# RTS591x register map
Vendor: Realtek Semiconductor Corp.; Series: RTS591x Series; File version: 1.0
CPU: ARMV8MML r0p0, little endian, MPU, FPU, VTOR, 3 interrupt priority bits, 4 SAU regions
Registers are 32-bit, read-write, reset 0x0 unless marked. A register's access mark holds for its fields unless they carry their own. Offsets are from the block's base; [hi:lo] are bit positions.

## RTC — RTC Controller
Base 0x4000C100
0x00 SEC 8-bit — SECOND REGISTER
0x01 SECALARM 8-bit — SECOND ALARM REGISTER
0x02 MIN 8-bit — MINUTES REGISTER
0x03 MINALARM 8-bit — MINUTES ALARM REGISTER
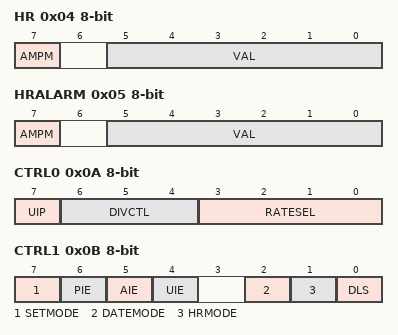
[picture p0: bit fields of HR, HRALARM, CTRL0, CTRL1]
0x04 HR 8-bit — HOUR REGISTER
  [7] AMPM — AM or PM Mode
  [5:0] VAL — Value of Hour
0x05 HRALARM 8-bit — HOUR ALARM REGISTER
  [7] AMPM — AM or PM Mode of Hour Alarm
  [5:0] VAL — Value of Hour Alarm
0x06 DAYWEEK 8-bit — DAY OF WEEK REGISTER
0x07 DAYMONTH 8-bit — DAY OF MONTH REGISTER
0x08 MONTH 8-bit
0x09 YEAR 8-bit
0x0A CTRL0 8-bit — CONTROL REGISTER #0
  [7] UIP — Update In Progress
    0=NOT_IN_PROGRESS (Time registers will not update in 244us); 1=IN_PROGRESS (Time registers will update in 244us)
  [6:4] DIVCTL — Divider Chain Control
    1=NORMAL (Normal operation); 6=DVDRST (Divider Chain Reset); other=NOT_USED (Do not use.)
  [3:0] RATESEL — Periodic Interrupt Rate Select
    0=NO_INTERRUPT; 1=3.906250ms (Divider chain is 7); 2=7.812500ms (Divider chain is 8); 3=0.122070ms (Divider chain is 2); 4=0.244141ms (Divider chain is 3); 5=0.488281ms (Divider chain is 4); 6=0.976562ms (Divider chain is 5); 7=1.953125ms (Divider chain is 6); 10=15.625000ms (Divider chain is 9); 11=31.250000ms (Divider chain is 10); 12=62.500000ms (Divider chain is 11); 13=125.000000ms (Divider chain is 12); 14=250.000000ms (Divider chain is 13); 15=500.000000ms (Divider chain is 14); other=NOT_USED (Do not use.)
0x0B CTRL1 8-bit — CONTROL REGISTER #1
  [7] SETMODE — Set Enable
    0=UPDATE (Time updates normally); 1=NO_UPDATE
  [6] PIE — Periodic Interrupt Enable
    0=DISBLE (Disable periodic interrupt); 1=ENABLE (Enable periodic interrupt)
  [5] AIE — Alarm Interrupt Enable
    0=DISBLE (Disable alarm interrupt); 1=ENABLE (Enable alarm interrupt)
  [4] UIE — Update Ended Interrupt Enable
    0=DISBLE (Disable update ended interrupt); 1=ENABLE (Enable update ended interrupt)
  [2] DATEMODE — Date Mode Selection
    0=BCD (Data shows in BCD format.); 1=BIN (Data shows in binary format.)
  [1] HRMODE — Hour Mode Selection
    0=MODE12 (12 hoour mode); 1=MODE24 (24 hour mode)
  [0] DLS — Daylight Saving Enable
    0=DISABLE (Disable daylight Savings control); 1=ENABLE (Enable daylight Savings control)
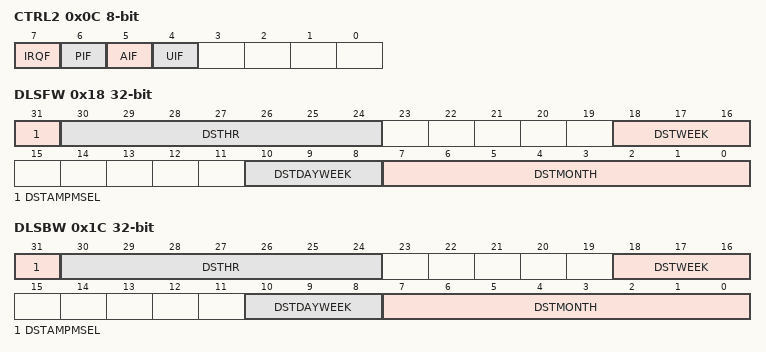
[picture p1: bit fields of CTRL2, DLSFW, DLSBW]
0x0C CTRL2 8-bit — CONTROL REGISTER #2
  [7] IRQF — Interrupt Flag
    0=INACTIVE (None of [6:4] bits in this register are active); 1=ACTIVE (Any [6:4] bits in this register are active)
  [6] PIF — Periodic Interrupt Flag
    0=NOT_OCCURED (Periodic Interrupt event has not occurred); 1=OCCURED (Periodic Interrupt event has occurred)
  [5] AIF — Alarm Interrupt Flag
    0=NOT_OCCURED (Alarm event has not occurred); 1=OCCURED (Alarm event has occurred)
  [4] UIF — Update Interrupt Flag
    0=NOT_OCCURED (Time and Date update has completed since the last time this register was read); 1=OCCURED (Time and Data update has not completed since the last time this register was read)
0x0D DAYWEEKALARM 8-bit — DAY OF WEEK ALARM REGISTER
0x0E DAYMONTHALARM 8-bit — DAY OF MONTH ALARM REGISTER
0x18 DLSFW (reset mask 0xFF) — DAYLIGHT SAVINGS FORWARD REGISTER
  [31] DSTAMPMSEL — Daylight Saving Forward AM/PM
  [30:24] DSTHR — Daylight Saving Forward Hour
  [18:16] DSTWEEK — Daylight Saving Forward Week
  [10:8] DSTDAYWEEK — Daylight Saving Forward Day of Week
  [7:0] DSTMONTH — Daylight Saving Forward Month
0x1C DLSBW (reset mask 0xFF) — DAYLIGHT SAVINGS BACKWARD REGISTER
  [31] DSTAMPMSEL — Daylight Saving Backward AM/PM
  [30:24] DSTHR — Daylight Saving Backward Hour
  [18:16] DSTWEEK — Daylight Saving Backward Week
  [10:8] DSTDAYWEEK — Daylight Saving Backward Day of Week
  [7:0] DSTMONTH — Daylight Saving Backward Month
0x20 WEEK 8-bit
